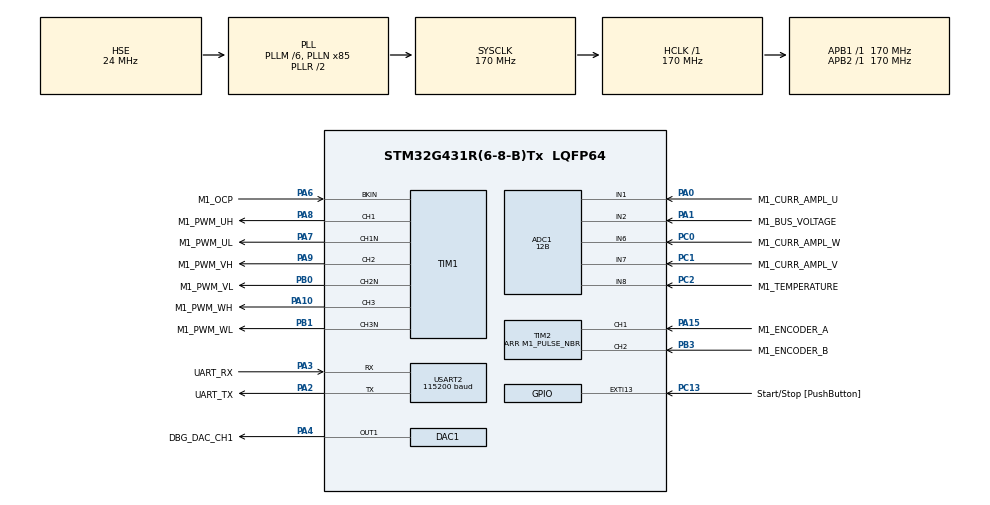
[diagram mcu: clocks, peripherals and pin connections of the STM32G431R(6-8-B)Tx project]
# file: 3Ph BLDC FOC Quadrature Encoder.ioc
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ADC1.Channel-1\#ChannelRegularConversion=ADC_CHANNEL_2
ADC1.Channel-2\#ChannelRegularConversion=ADC_CHANNEL_8
ADC1.ClockPrescaler=ADC_CLOCK_ASYNC_DIV1
ADC1.ContinuousConvMode=DISABLE
ADC1.DMAContinuousRequests=DISABLE
ADC1.DataAlign=ADC_DATAALIGN_LEFT
ADC1.DiscontinuousConvMode=DISABLE
ADC1.EOCSelection=ADC_EOC_SINGLE_CONV
ADC1.EnableAnalogWatchDog1=false
ADC1.EnableAnalogWatchDog2=false
ADC1.EnableAnalogWatchDog3=false
ADC1.EnableInjectedConversion=ENABLE
ADC1.EnableRegularConversion=ENABLE
ADC1.ExternalTrigConv=ADC_SOFTWARE_START
ADC1.ExternalTrigConvEdge=ADC_EXTERNALTRIGCONVEDGE_NONE
ADC1.ExternalTrigInjecConv=ADC_EXTERNALTRIGINJEC_T1_TRGO
ADC1.ExternalTrigInjecConvEdge=ADC_EXTERNALTRIGINJECCONV_EDGE_RISING
ADC1.InjNumberOfConversion=3
ADC1.InjectedChannel-1\#ChannelInjectedConversion=ADC_CHANNEL_1
ADC1.InjectedChannel-2\#ChannelInjectedConversion=ADC_CHANNEL_7
ADC1.InjectedChannel-3\#ChannelInjectedConversion=ADC_CHANNEL_6
ADC1.InjectedConvMode=None
ADC1.InjectedOffset-1\#ChannelInjectedConversion=0
ADC1.InjectedOffset-2\#ChannelInjectedConversion=0
ADC1.InjectedOffset-3\#ChannelInjectedConversion=0
ADC1.InjectedOffsetNumber-1\#ChannelInjectedConversion=ADC_OFFSET_NONE
ADC1.InjectedOffsetNumber-2\#ChannelInjectedConversion=ADC_OFFSET_NONE
ADC1.InjectedOffsetNumber-3\#ChannelInjectedConversion=ADC_OFFSET_NONE
ADC1.InjectedRank-1\#ChannelInjectedConversion=1
ADC1.InjectedRank-2\#ChannelInjectedConversion=2
ADC1.InjectedRank-3\#ChannelInjectedConversion=3
ADC1.InjectedSamplingTime-1\#ChannelInjectedConversion=ADC_SAMPLETIME_6CYCLES_5
ADC1.InjectedSamplingTime-2\#ChannelInjectedConversion=ADC_SAMPLETIME_6CYCLES_5
ADC1.InjectedSamplingTime-3\#ChannelInjectedConversion=ADC_SAMPLETIME_6CYCLES_5
ADC1.LowPowerAutoWait=DISABLE
ADC1.NbrOfConversion=2
ADC1.NbrOfConversionFlag=1
ADC1.Offset-1\#ChannelRegularConversion=0
ADC1.Offset-2\#ChannelRegularConversion=0
ADC1.OffsetNumber-1\#ChannelRegularConversion=ADC_OFFSET_NONE
ADC1.OffsetNumber-2\#ChannelRegularConversion=ADC_OFFSET_NONE
ADC1.Overrun=ADC_OVR_DATA_PRESERVED
ADC1.Rank-1\#ChannelRegularConversion=1
ADC1.Rank-2\#ChannelRegularConversion=2
ADC1.Resolution=ADC_RESOLUTION_12B
ADC1.SamplingTime-1\#ChannelRegularConversion=ADC_SAMPLETIME_47CYCLES_5
ADC1.SamplingTime-2\#ChannelRegularConversion=ADC_SAMPLETIME_47CYCLES_5
ADC1.ScanConvMode=ADC_SCAN_ENABLE
ADC1.master=1
DAC1.DAC_OutputBuffer=DAC_OUTPUTBUFFER_DISABLE
DAC1.DAC_Trigger_OUT1=DAC_TRIGGER_SOFTWARE
Dma.Request0=USART2_RX
Dma.Request1=USART2_TX
Dma.USART2_RX.0.Direction=DMA_PERIPH_TO_MEMORY
Dma.USART2_RX.0.EventEnable=DISABLE
Dma.USART2_RX.0.Instance=DMA1_Channel1
Dma.USART2_RX.0.MemDataAlignment=DMA_MDATAALIGN_BYTE
Dma.USART2_RX.0.MemInc=DMA_MINC_ENABLE
Dma.USART2_RX.0.Mode=DMA_NORMAL
Dma.USART2_RX.0.PeriphDataAlignment=DMA_PDATAALIGN_BYTE
Dma.USART2_RX.0.PeriphInc=DMA_PINC_DISABLE
Dma.USART2_RX.0.Polarity=HAL_DMAMUX_REQ_GEN_RISING
Dma.USART2_RX.0.Priority=DMA_PRIORITY_LOW
Dma.USART2_RX.0.RequestNumber=1
Dma.USART2_RX.0.SignalID=NONE
Dma.USART2_RX.0.SyncEnable=DISABLE
Dma.USART2_RX.0.SyncPolarity=HAL_DMAMUX_SYNC_NO_EVENT
Dma.USART2_RX.0.SyncRequestNumber=1
Dma.USART2_RX.0.SyncSignalID=NONE
Dma.USART2_TX.1.Direction=DMA_MEMORY_TO_PERIPH
Dma.USART2_TX.1.EventEnable=DISABLE
Dma.USART2_TX.1.Instance=DMA1_Channel2
Dma.USART2_TX.1.MemDataAlignment=DMA_MDATAALIGN_BYTE
Dma.USART2_TX.1.MemInc=DMA_MINC_ENABLE
Dma.USART2_TX.1.Mode=DMA_NORMAL
Dma.USART2_TX.1.PeriphDataAlignment=DMA_PDATAALIGN_BYTE
Dma.USART2_TX.1.PeriphInc=DMA_PINC_DISABLE
Dma.USART2_TX.1.Polarity=HAL_DMAMUX_REQ_GEN_RISING
Dma.USART2_TX.1.Priority=DMA_PRIORITY_LOW
Dma.USART2_TX.1.RequestNumber=1
Dma.USART2_TX.1.SignalID=NONE
Dma.USART2_TX.1.SyncEnable=DISABLE
Dma.USART2_TX.1.SyncPolarity=HAL_DMAMUX_SYNC_NO_EVENT
Dma.USART2_TX.1.SyncRequestNumber=1
Dma.USART2_TX.1.SyncSignalID=NONE
ExtraMW=MotorControl
ExtraMW.MotorControl.Config=MotorControl
ExtraMW.MotorControl.Mode=MotorControl
ExtraMW.MotorControl.Root=MCSDK_v6.3.0-Full/MotorControl
ExtraMW.MotorControl.Template=templates
FREERTOS.Tasks01=mediumFrequency,0,128,startMediumFrequencyTask,As weak,NULL,Dynamic,NULL,NULL;safety,1,128,StartSafetyTask,As external,NULL,Dynamic,NULL,NULL
Mcu.Family=STM32G4
Mcu.Name=STM32G431R(6-8-B)Tx
Mcu.Package=LQFP64
MotorControl.ADC_AHBPERIPH=RCC_AHBPeriph_ADC1
MotorControl.ADC_CLOCK_WB_DIV=1
MotorControl.ADC_PERIPH=ADC1
MotorControl.ADC_REFERENCE_VOLTAGE=3.3
MotorControl.BOARD=NUCLEO-G431RB
MotorControl.BUS_VOLTAGE_READING=true
MotorControl.CCMRAM_ENABLED=false
MotorControl.CLOCK_FREQUENCY=CPU_CLK_170_MHZ
MotorControl.CLOCK_SOURCE=EXTERNAL
MotorControl.CPU_CLK_170_MHZ=true
MotorControl.CTLBOARD_NAME=NUCLEO-G431RB
MotorControl.CUBE_MX_VER=6.12.0
MotorControl.CURRENT_READING_TOPOLOGY=THREE_SHUNT
MotorControl.CURR_SAMPLING_TIME=6
MotorControl.DAC_NAME=DAC1
MotorControl.DBG_MCU_LOAD_MEASURE=false
MotorControl.DEBUG_DAC_CH1=true
MotorControl.DEBUG_DAC_CH1_EN=true
MotorControl.DEBUG_DAC_FUNCTIONALITY_EN=true
MotorControl.DRIVES_NUMBER_SELECTION=SINGLEDRIVE
MotorControl.DRIVE_NUMBER=1
MotorControl.DRIVE_TYPE=FOC
MotorControl.EMERGENCY_STOP_GPIO_PIN=LL_GPIO_PIN_6
MotorControl.EMERGENCY_STOP_GPIO_PORT=GPIOA
MotorControl.ENCODER=true
MotorControl.ENCODER_AVAILABLE=true
MotorControl.ENCODER_PPR=2048
MotorControl.ENC_A_GPIO_PIN=LL_GPIO_PIN_15
MotorControl.ENC_A_GPIO_PORT=GPIOA
MotorControl.ENC_B_GPIO_PIN=LL_GPIO_PIN_3
MotorControl.ENC_B_GPIO_PORT=GPIOB
MotorControl.ENC_ICx_FILTER=119
MotorControl.ENC_INVERT_SPEED=false
MotorControl.ENC_TIMER_SELECTION=ENC_TIM2
MotorControl.ENC_USE_CH3=false
MotorControl.EXT_CLK_24_MHZ=true
MotorControl.EXT_CLOCK_FREQUENCY=EXT_CLK_24_MHZ
MotorControl.FEEDBACK_NET_FILTERING=false
MotorControl.HALL_SENSORS_AVAILABLE=false
MotorControl.HIGH_SIDE_IDLE_STATE=false
MotorControl.HWV_CS=ThreeShunt_AmplifiedCurrents
MotorControl.HWV_OCP=OnPowerStageOCP
MotorControl.HWV_PWM=DrivingHighAndLowSides
MotorControl.HW_COMPLEMENTED_LOW_SIDE=false
MotorControl.HW_DEAD_TIME_NS=1000
MotorControl.IPs=CORDIC,SYS,NVIC,RCC,MotorControl,TIM1,ADC1,TIM2,DAC1,USART2,FREERTOS,DMA
MotorControl.LOW_MEMORY_FOOTPRINT_REG=false
MotorControl.LOW_SIDE_IDLE_STATE=false
MotorControl.LOW_SIDE_SIGNALS_ENABLING=LS_PWM_TIMER
MotorControl.M1_ALIGNMENT_ANGLE_DEG=90
MotorControl.M1_ALIGNMENT_DURATION=700
MotorControl.M1_AMPLIFICATION_GAIN=5.18
MotorControl.M1_ANGC={0,0,0,0,0,0,0,0}
MotorControl.M1_AUXILIARY_SPEED_SENSOR=NONE
MotorControl.M1_BOARD_MAX_CURRENT=4.97
MotorControl.M1_BUS_VOLTAGE_READING=true
MotorControl.M1_COMMUTATION_STEP_TIME_BUF_SIZE=12
MotorControl.M1_CONSTANT1_D=1857278
MotorControl.M1_CONSTANT1_Q=1857278
MotorControl.M1_CONSTANT2_QD=16970
MotorControl.M1_CS_ADC_NUM=1
MotorControl.M1_CS_ADC_PHASE_SHARED=NONE
MotorControl.M1_CS_ADC_U=ADC1
MotorControl.M1_CS_ADC_V=ADC1
MotorControl.M1_CS_ADC_W=ADC1
MotorControl.M1_CS_CHANNEL_U=1
MotorControl.M1_CS_CHANNEL_V=7
MotorControl.M1_CS_CHANNEL_W=6
MotorControl.M1_CURRENT_AMPLIFICATION_TOPO=EXTERNAL
MotorControl.M1_CURRENT_SENSING_TOPO=THREE_SHUNT
MotorControl.M1_CURR_SAMPLING_TIME=6
MotorControl.M1_DBG_OPEN_LOOP_ENABLE=false
MotorControl.M1_DC_CURRENT_RS_MEAS=4.97
MotorControl.M1_DEFAULT_CONTROL_MODE=STC_SPEED_MODE
MotorControl.M1_DEFAULT_FLUX_COMPONENT=0
MotorControl.M1_DEFAULT_TARGET_SPEED_RPM=3600
MotorControl.M1_DEFAULT_TORQUE_COMPONENT=0
MotorControl.M1_DISCONTINUOUS_PWM=false
MotorControl.M1_DP_TOPOLOGY=NONE
MotorControl.M1_DRIVE_TYPE=FOC
MotorControl.M1_ENCODER_PPR=2048
MotorControl.M1_ENC_AVERAGING_FIFO_DEPTH=8
MotorControl.M1_ENC_A_GPIO_PIN=LL_GPIO_PIN_15
MotorControl.M1_ENC_A_GPIO_PORT=GPIOA
MotorControl.M1_ENC_B_GPIO_PIN=LL_GPIO_PIN_3
MotorControl.M1_ENC_B_GPIO_PORT=GPIOB
MotorControl.M1_ENC_ICx_FILTER=119
MotorControl.M1_ENC_TIMER_SELECTION=ENC_TIM2
MotorControl.M1_ENC_USE_CH3=false
MotorControl.M1_FEED_FORWARD_CURRENT_REG_ENABLING=false
MotorControl.M1_FINAL_I_ALIGNMENT=4.97
MotorControl.M1_FLUX_WEAKENING_ENABLING=false
MotorControl.M1_FW_KIDIV=32768
MotorControl.M1_FW_KI_GAIN=5000
MotorControl.M1_FW_KPDIV=32768
MotorControl.M1_FW_KP_GAIN=3000
MotorControl.M1_FW_VOLTAGE_REF=985
MotorControl.M1_HALL_PHASE_SHIFT=300
MotorControl.M1_HALL_SENSORS_PLACEMENT=DEGREES_120
MotorControl.M1_HIGH_SIDE_IDLE_STATE=false
MotorControl.M1_HW_DEAD_TIME_NS=1000
MotorControl.M1_ICL_ENABLED=false
MotorControl.M1_ID_DEMAG=-4.97
MotorControl.M1_IQMAX=4.97
MotorControl.M1_LDLQ_RATIO=1.000
MotorControl.M1_LOW_SIDE_IDLE_STATE=false
MotorControl.M1_LOW_SIDE_SIGNALS_ENABLING=LS_PWM_TIMER
MotorControl.M1_LS=0.00224
MotorControl.M1_MAX_APPLICATION_SPEED=10000
MotorControl.M1_MAX_MODULATION_INDEX=100
MotorControl.M1_MIN_APPLICATION_SPEED=0
MotorControl.M1_MOTOR_MAX_SPEED_RPM=10000
MotorControl.M1_MOTOR_NAME=Maxon EC45 Flat 42.9mm
MotorControl.M1_MOTOR_RATED_FLUX=0.032761925
MotorControl.M1_MOTOR_VOLTAGE_CONSTANT=5.4
MotorControl.M1_MTPA_ENABLING=false
MotorControl.M1_NOMINAL_BUS_VOLTAGE_V=24
MotorControl.M1_NOMINAL_CURRENT=4.97
MotorControl.M1_OCP_BKIN_FILTER=3
MotorControl.M1_OCP_BKIN_MODE=EXT_MODE
MotorControl.M1_OCP_BKIN_POLARITY=EMSTOP_ACTIVE_LOW
MotorControl.M1_OCP_DESTINATION=TIM_BKIN
MotorControl.M1_OCP_TOPOLOGY=EXTERNAL
MotorControl.M1_OFST={0,0,0,0,0,0,0,0}
MotorControl.M1_ON_OVER_VOLTAGE=TURN_OFF_PWM
MotorControl.M1_OVERMODULATION=false
MotorControl.M1_OVP_THRESHOLD_HIGH=29
MotorControl.M1_OV_TEMPERATURE_HYSTERESIS_C=10
MotorControl.M1_OV_TEMPERATURE_PROT_ENABLING=true
MotorControl.M1_OV_TEMPERATURE_THRESHOLD_C=110
MotorControl.M1_OV_VOLTAGE_PROT_ENABLING=true
MotorControl.M1_OV_VOLTAGE_THRESHOLD_V=29
MotorControl.M1_PID_FLUX_KD_DEFAULT=100
MotorControl.M1_PID_FLUX_KI_DEFAULT=2461
MotorControl.M1_PID_FLUX_KP_DEFAULT=2283
MotorControl.M1_PID_SPEED_KD_DEFAULT=0
MotorControl.M1_PID_SPEED_KI_DEFAULT=430
MotorControl.M1_PID_SPEED_KP_DEFAULT=2222
MotorControl.M1_PID_TORQUE_KD_DEFAULT=100
MotorControl.M1_PID_TORQUE_KI_DEFAULT=2461
MotorControl.M1_PID_TORQUE_KP_DEFAULT=2283
MotorControl.M1_POLE_PAIR_NUM=8
MotorControl.M1_POSITION_CTRL_ENABLING=true
MotorControl.M1_POSITION_CTRL_KDDIV=16
MotorControl.M1_POSITION_CTRL_KD_GAIN=1000
MotorControl.M1_POSITION_CTRL_KIDIV=32768
MotorControl.M1_POSITION_CTRL_KI_GAIN=1000
MotorControl.M1_POSITION_CTRL_KPDIV=1024
MotorControl.M1_POSITION_CTRL_KP_GAIN=10000
MotorControl.M1_POSITION_LOOP_FREQUENCY_HZ=1000
MotorControl.M1_POTENTIOMETER_ENABLE=false
MotorControl.M1_POWERBOARD_NAME=X-NUCLEO-IHM08M1
MotorControl.M1_PWM_CHARGE_BOOT_CAP_DUTY_CYCLES=0.000
MotorControl.M1_PWM_CHARGE_BOOT_CAP_MS=10
MotorControl.M1_PWM_DRIVER_PN=L6398
MotorControl.M1_PWM_FREQUENCY=16000
MotorControl.M1_PWM_TIMER_BRK_IRQ=TIM1_BRK_TIM15
MotorControl.M1_PWM_TIMER_SELECTION=PWM_TIM1
MotorControl.M1_PWM_TIMER_UP_IRQ=TIM1_UP_TIM16
MotorControl.M1_REGULATION_EXECUTION_RATE=1
MotorControl.M1_RS=4.83
MotorControl.M1_RSHUNT=0.01
MotorControl.M1_SEGDIV=0
MotorControl.M1_SHARED_SIGNAL_ENABLE=false
MotorControl.M1_SPD_DIFFERENTIAL_TERM_ENABLING=false
MotorControl.M1_SPEED_SENSOR=QUAD_ENCODER
MotorControl.M1_SP_KDDIV=16
MotorControl.M1_SP_KIDIV=16384
MotorControl.M1_SP_KPDIV=128
MotorControl.M1_SS_MEAS_ERRORS_BEFORE_FAULTS=3
MotorControl.M1_SW_DEADTIME_NS=850
MotorControl.M1_T0_C=25
MotorControl.M1_TEMPERATURE_READING=true
MotorControl.M1_TEMP_ADC_SAMPLING_TIME=47
MotorControl.M1_TEMP_FDBK_ADC=ADC1
MotorControl.M1_TEMP_FDBK_CHANNEL=ADC_CHANNEL_8
MotorControl.M1_TF_KDDIV=8192
MotorControl.M1_TF_KIDIV=512
MotorControl.M1_TF_KPDIV=64
MotorControl.M1_TNOISE_NS=1000
MotorControl.M1_TRISE_NS=1000
MotorControl.M1_T_MAX=110
MotorControl.M1_UD_VOLTAGE_THRESHOLD_V=10
MotorControl.M1_USE_INTERNAL_OPAMP=false
MotorControl.M1_UV_VOLTAGE_PROT_ENABLING=true
MotorControl.M1_V0_V=1.055
MotorControl.M1_VBUS_ADC=ADC1
MotorControl.M1_VBUS_ADC_SAMPLING_TIME=47
MotorControl.M1_VBUS_CHANNEL=ADC_CHANNEL_2
MotorControl.M1_VBUS_PARTITIONING_FACTOR=0.052164840897235255
MotorControl.M1_dV_dT=0.023
MotorControl.MAX_READABLE_CURRENT=31.845
MotorControl.MCPA_OVER_UART_A_STREAM=10
MotorControl.MCP_ASPEP_OVER_UART=true
MotorControl.MCP_ASYNC_EN=true
MotorControl.MCP_ASYNC_OVER_ASPEP_EN=true
MotorControl.MCP_ASYNC_OVER_UART_A_EN=true
MotorControl.MCP_DMACH_RX_UART_A=1
MotorControl.MCP_DMACH_TX_UART_A=2
MotorControl.MCP_DMA_RX_UART_A=DMA1
MotorControl.MCP_DMA_TX_UART_A=DMA1
MotorControl.MCP_EN=true
MotorControl.MCP_IRQ_HANDLER_DMA_RX_UART_A=DMA1_Channel1_IRQHandler
MotorControl.MCP_IRQ_HANDLER_UART_A=USART2_IRQHandler
MotorControl.MCP_OVER_ASPEP_EN=true
MotorControl.MCP_OVER_STLNK_EN=false
MotorControl.MCP_OVER_UART_A_EN=true
MotorControl.MCP_OVER_UART_B_EN=false
MotorControl.MCP_RX_SYNC_PAYLOAD_MAX=128
MotorControl.MCP_TX_ASYNC_PAYLOAD_MAX_UART_A=2048
MotorControl.MCP_TX_SYNC_PAYLOAD_MAX=128
MotorControl.MCU=STM32G431RB
MotorControl.MCU_FAMILY=STM32G4
MotorControl.MCU_LINE=STM32G4x1
MotorControl.MCU_NAME=STM32G431R(6-8-B)Tx
MotorControl.MCU_PACKAGE=LQFP64
MotorControl.MCU_TYPE=STM32G431RB
MotorControl.MCU_USERNAME=STM32G431RBTx
MotorControl.MC_WORKBENCH_VERSION=6.3.0
MotorControl.MOTOR_PROFILER=false
MotorControl.MOTOR_TYPE=PMSM
MotorControl.ON_OVER_VOLTAGE=TURN_OFF_PWM
MotorControl.OV_TEMPERATURE_PROT_ENABLING=true
MotorControl.OV_VOLTAGE_PROT_ENABLING=true
MotorControl.PHASE_UH_GPIO_PIN=LL_GPIO_PIN_8
MotorControl.PHASE_UH_GPIO_PORT=GPIOA
MotorControl.PHASE_UH_POLARITY=H_ACTIVE_HIGH
MotorControl.PHASE_UL_GPIO_PIN=LL_GPIO_PIN_7
MotorControl.PHASE_UL_GPIO_PORT=GPIOA
MotorControl.PHASE_UL_POLARITY=L_ACTIVE_LOW
MotorControl.PHASE_U_CURR_ADC=ADC1
MotorControl.PHASE_U_CURR_CHANNEL=ADC_CHANNEL_1
MotorControl.PHASE_U_GPIO_PIN=LL_GPIO_PIN_0
MotorControl.PHASE_U_GPIO_PORT=GPIOA
MotorControl.PHASE_VH_GPIO_PIN=LL_GPIO_PIN_9
MotorControl.PHASE_VH_GPIO_PORT=GPIOA
MotorControl.PHASE_VH_POLARITY=H_ACTIVE_HIGH
MotorControl.PHASE_VL_GPIO_PIN=LL_GPIO_PIN_0
MotorControl.PHASE_VL_GPIO_PORT=GPIOB
MotorControl.PHASE_VL_POLARITY=L_ACTIVE_LOW
MotorControl.PHASE_V_CURR_ADC=ADC1
MotorControl.PHASE_V_CURR_CHANNEL=ADC_CHANNEL_7
MotorControl.PHASE_V_GPIO_PIN=LL_GPIO_PIN_1
MotorControl.PHASE_V_GPIO_PORT=GPIOC
MotorControl.PHASE_WH_GPIO_PIN=LL_GPIO_PIN_10
MotorControl.PHASE_WH_GPIO_PORT=GPIOA
MotorControl.PHASE_WH_POLARITY=H_ACTIVE_HIGH
MotorControl.PHASE_WL_GPIO_PIN=LL_GPIO_PIN_1
MotorControl.PHASE_WL_GPIO_PORT=GPIOB
MotorControl.PHASE_WL_POLARITY=L_ACTIVE_LOW
MotorControl.PHASE_W_CURR_ADC=ADC1
MotorControl.PHASE_W_CURR_CHANNEL=ADC_CHANNEL_6
MotorControl.PHASE_W_GPIO_PIN=LL_GPIO_PIN_0
MotorControl.PHASE_W_GPIO_PORT=GPIOC
MotorControl.POTENTIOMETER_READING=false
MotorControl.PWM_FREQUENCY=16000
MotorControl.PWM_TIMER_SELECTION=PWM_TIM1
MotorControl.REGULATION_EXECUTION_RATE=1
MotorControl.RTOS=FREERTOS
MotorControl.RTOS_IRQ_NAME_WB2MX=TIM6_DAC_IRQn
MotorControl.RTOS_TIMER=TIM6
MotorControl.RTOS_USE_IRQ=true
MotorControl.R_BRAKE_SWITCH_OFF_THRES_V=23
MotorControl.SINGLEDRIVE=true
MotorControl.SPD_DIFFERENTIAL_TERM_ENABLING=false
MotorControl.SPEED_SENSOR_SELECTION=ENCODER
MotorControl.START_STOP_BTN=true
MotorControl.START_STOP_GPIO_PIN=LL_GPIO_PIN_13
MotorControl.START_STOP_GPIO_PORT=GPIOC
MotorControl.START_STOP_POLARITY=DIN_ACTIVE_LOW
MotorControl.START_STOP_POLARITY_EDGE=GPIO_NOPULL
MotorControl.STM32G431RB=true
MotorControl.SW_DEADTIME_NS=850
MotorControl.TEMPERATURE_READING=true
MotorControl.TEMP_ADC_SAMPLING_TIME=47
MotorControl.TEMP_FDBK_ADC=ADC1
MotorControl.TEMP_FDBK_CHANNEL=ADC_CHANNEL_8
MotorControl.TEMP_FDBK_GPIO_PIN=LL_GPIO_PIN_2
MotorControl.TEMP_FDBK_GPIO_PORT=GPIOC
MotorControl.TFDIFFERENTIAL_TERM_ENABLING=false
MotorControl.THREE_SHUNT=true
MotorControl.TRISE_NS=1000
MotorControl.USART_RX_GPIO_PIN=LL_GPIO_PIN_3
MotorControl.USART_RX_GPIO_PORT=GPIOA
MotorControl.USART_SELECTION=USE_USART2
MotorControl.USART_SELECTION_A=USART2
MotorControl.USART_SPEED=115200
MotorControl.USART_TX_GPIO_PIN=LL_GPIO_PIN_2
MotorControl.USART_TX_GPIO_PORT=GPIOA
MotorControl.USE_3OPAMPS=false
MotorControl.USE_INTERNAL_OPAMP=false
MotorControl.UV_VOLTAGE_PROT_ENABLING=true
MotorControl.VBUS_ADC=ADC1
MotorControl.VBUS_ADC_SAMPLING_TIME=47
MotorControl.VBUS_CHANNEL=ADC_CHANNEL_2
MotorControl.VBUS_GPIO_PIN=LL_GPIO_PIN_1
MotorControl.VBUS_GPIO_PORT=GPIOA
MotorControl.WB_UI_CUTOFF_FREQUENCY=6000
MotorControl.WB_UI_DAC_CH1_PIN=PA4
MotorControl.WB_UI_ENCODER_HAS_INDEX_PIN=false
MotorControl.WB_UI_FLUX_TARGET=0
MotorControl.WB_UI_FRICTION=14
MotorControl.WB_UI_INERTIA=9.25
MotorControl.WB_UI_MAGNETIC_STRUCTURE=SM-PMSM
MotorControl.WB_UI_MAX_CURRENT=4.97
MotorControl.WB_UI_MAX_NOMINAL_DC_VOLTAGE=24
MotorControl.WB_UI_MAX_PWMFREQUENCY=100000
MotorControl.WB_UI_MOTOR_DESCRIPTION=brushless DC motor with encoder and Z Index
MotorControl.WB_UI_OCP_DISABLING_ENABLE=false
MotorControl.WB_UI_OCP_THRESHOLD=30
MotorControl.WB_UI_PW_BOARD_MAX_RATED_CURRENT=30
MotorControl.WB_UI_PW_BOARD_MAX_VOLTAGE=48
MotorControl.WB_UI_PW_BOARD_MIN_VOLTAGE=10
MotorControl.WB_UI_VPOL=1.71
MotorControl.WB_to_Mx_template_version=24-04-17
MotorControl.WB_to_Mx_version=6.2.3
NVIC.ADC1_2_IRQn=true\:7\:0\:true\:true\:false\:5\:true\:true\:true\:true
NVIC.DMA1_Channel1_IRQn=true\:8\:0\:true\:true\:false\:2\:true\:true\:true\:true
NVIC.EXTI15_10_IRQn=true\:8\:0\:true\:true\:false\:7\:true\:true\:true\:true
NVIC.PriorityGroup=NVIC_PRIORITYGROUP_4
NVIC.TIM1_BRK_TIM15_IRQn=true\:9\:0\:true\:true\:false\:3\:true\:true\:true\:true
NVIC.TIM1_UP_TIM16_IRQn=true\:5\:0\:true\:true\:false\:4\:true\:true\:true\:true
NVIC.TIM2_IRQn=true\:8\:0\:true\:true\:false\:6\:true\:true\:true\:true
NVIC.TIM6_DAC_IRQn=true\:0\:0\:false\:false\:true\:false\:false\:true\:true
NVIC.TimeBase=TIM6_DAC_IRQn
NVIC.TimeBaseIP=TIM6
NVIC.USART2_IRQn=true\:8\:0\:true\:true\:false\:1\:true\:true\:true\:true
PA0.GPIO_Label=M1_CURR_AMPL_U
PA0.Mode=IN1-Single-Ended
PA0.Signal=ADC1_IN1
PA1.GPIO_Label=M1_BUS_VOLTAGE
PA1.Mode=IN2-Single-Ended
PA1.Signal=ADC1_IN2
PA10.GPIO_Label=M1_PWM_WH
PA10.GPIO_PuPd=GPIO_PULLDOWN
PA10.GPIO_Speed=GPIO_SPEED_FREQ_HIGH
PA10.Signal=S_TIM1_CH3
PA13.GPIO_Label=TMS
PA13.Mode=Serial_Wire
PA13.Signal=SYS_JTMS-SWDIO
PA14.GPIO_Label=TCK
PA14.Mode=Serial_Wire
PA14.Signal=SYS_JTCK-SWCLK
PA15.GPIO_Label=M1_ENCODER_A
PA15.Signal=S_TIM2_CH1
PA2.GPIO_Label=UART_TX
PA2.GPIO_Mode=GPIO_MODE_AF_PP
PA2.GPIO_PuPd=GPIO_NOPULL
PA2.GPIO_Speed=GPIO_SPEED_FREQ_LOW
PA2.Mode=Asynchronous
PA2.Signal=USART2_TX
PA3.GPIO_Label=UART_RX
PA3.GPIO_Mode=GPIO_MODE_AF_PP
PA3.GPIO_PuPd=GPIO_NOPULL
PA3.GPIO_Speed=GPIO_SPEED_FREQ_LOW
PA3.Mode=Asynchronous
PA3.Signal=USART2_RX
PA4.GPIO_Label=DBG_DAC_CH1
PA4.Signal=COMP_DAC11_group
PA6.GPIO_Label=M1_OCP
PA6.GPIO_PuPd=GPIO_PULLUP
PA6.Mode=Activate-Break-Input
PA6.Signal=TIM1_BKIN
PA7.GPIO_Label=M1_PWM_UL
PA7.GPIO_PuPd=GPIO_PULLUP
PA7.GPIO_Speed=GPIO_SPEED_FREQ_HIGH
PA7.Mode=PWM Generation1 CH1 CH1N
PA7.Signal=TIM1_CH1N
PA8.GPIO_Label=M1_PWM_UH
PA8.GPIO_PuPd=GPIO_PULLDOWN
PA8.GPIO_Speed=GPIO_SPEED_FREQ_HIGH
PA8.Signal=S_TIM1_CH1
PA9.GPIO_Label=M1_PWM_VH
PA9.GPIO_PuPd=GPIO_PULLDOWN
PA9.GPIO_Speed=GPIO_SPEED_FREQ_HIGH
PA9.Signal=S_TIM1_CH2
PB0.GPIO_Label=M1_PWM_VL
PB0.GPIO_PuPd=GPIO_PULLUP
PB0.GPIO_Speed=GPIO_SPEED_FREQ_HIGH
PB0.Mode=PWM Generation2 CH2 CH2N
PB0.Signal=TIM1_CH2N
PB1.GPIO_Label=M1_PWM_WL
PB1.GPIO_PuPd=GPIO_PULLUP
PB1.GPIO_Speed=GPIO_SPEED_FREQ_HIGH
PB1.Mode=PWM Generation3 CH3 CH3N
PB1.Signal=TIM1_CH3N
PB3.GPIO_Label=M1_ENCODER_B
PB3.Signal=S_TIM2_CH2
PC0.GPIO_Label=M1_CURR_AMPL_W
PC0.Mode=IN6-Single-Ended
PC0.Signal=ADC1_IN6
PC1.GPIO_Label=M1_CURR_AMPL_V
PC1.Mode=IN7-Single-Ended
PC1.Signal=ADC1_IN7
PC13.GPIO_Label=Start/Stop [PushButton]
PC13.GPIO_ModeDefaultEXTI=GPIO_MODE_IT_FALLING
PC13.GPIO_PuPd=GPIO_NOPULL
PC13.Signal=GPXTI13
PC2.GPIO_Label=M1_TEMPERATURE
PC2.Mode=IN8-Single-Ended
PC2.Signal=ADC1_IN8
PF0-OSC_IN.Mode=HSE-External-Oscillator
PF0-OSC_IN.Signal=RCC_OSC_IN
PF1-OSC_OUT.Mode=HSE-External-Oscillator
PF1-OSC_OUT.Signal=RCC_OSC_OUT
ProjectManager.HeapSize=0x200
ProjectManager.StackSize=0x400
ProjectManager.TargetToolchain=STM32CubeIDE
RCC.ADC12CLockSelection=RCC_ADC12CLKSOURCE_PLL
RCC.ADC12Freq_Value=42500000
RCC.AHBFreq_Value=170000000
RCC.APB1Freq_Value=170000000
RCC.APB1TimFreq_Value=170000000
RCC.APB2Freq_Value=170000000
RCC.APB2TimFreq_Value=170000000
RCC.CK48CLockSelection=RCC_USBCLKSOURCE_PLL
RCC.CortexFreq_Value=170000000
RCC.EXTERNAL_CLOCK_VALUE=12288000
RCC.EnbaleCSS=true
RCC.HCLKFreq_Value=170000000
RCC.HSE_VALUE=24000000
RCC.HSI48_VALUE=48000000
RCC.HSI_VALUE=16000000
RCC.LSE_VALUE=32768
RCC.PLLM=RCC_PLLM_DIV6
RCC.PLLN=85
RCC.PLLP=RCC_PLLP_DIV8
RCC.PLLSourceVirtual=RCC_PLLSOURCE_HSE
RCC.PREFETCH_ENABLE=1
RCC.SYSCLKFreq_VALUE=170000000
RCC.SYSCLKSource=RCC_SYSCLKSOURCE_PLLCLK
RCC.USBFreq_Value=170000000
RCC.VCOOutputFreq_Value=340000000
SH.COMP_DAC11_group.0=DAC1_OUT1,DAC_OUT1
SH.S_TIM1_CH1.0=TIM1_CH1,PWM Generation1 CH1 CH1N
SH.S_TIM1_CH2.0=TIM1_CH2,PWM Generation2 CH2 CH2N
SH.S_TIM1_CH3.0=TIM1_CH3,PWM Generation3 CH3 CH3N
SH.S_TIM2_CH1.0=TIM2_CH1,Encoder_Interface
SH.S_TIM2_CH2.0=TIM2_CH2,Encoder_Interface
TIM1.AutoReloadPreload=TIM_AUTORELOAD_PRELOAD_DISABLE
TIM1.AutomaticOutput=TIM_AUTOMATICOUTPUT_DISABLE
TIM1.Break2Filter=3
TIM1.Break2Polarity=TIM_BREAK2POLARITY_HIGH
TIM1.Break2State=TIM_BREAK2_DISABLE
TIM1.BreakFilter=3
TIM1.BreakPolarity=TIM_BREAKPOLARITY_HIGH
TIM1.BreakState=TIM_BREAK_ENABLE
TIM1.Channel=TIM_CHANNEL_4
TIM1.Channel-PWM\ Generation1\ CH1\ CH1N=TIM_CHANNEL_1
TIM1.Channel-PWM\ Generation2\ CH2\ CH2N=TIM_CHANNEL_2
TIM1.Channel-PWM\ Generation3\ CH3\ CH3N=TIM_CHANNEL_3
TIM1.Channel-PWM\ Generation4\ No\ Output=TIM_CHANNEL_4
TIM1.ClearInputSource=TIM_CLEARINPUTSOURCE_NONE
TIM1.ClockDivision=TIM_CLOCKDIVISION_DIV2
TIM1.CounterMode=TIM_COUNTERMODE_CENTERALIGNED1
TIM1.DeadTime=((DEAD_TIME_COUNTS) / 2)
TIM1.LockLevel=TIM_LOCKLEVEL_OFF
TIM1.OC1Preload_PWM=ENABLE
TIM1.OC2Preload_PWM=ENABLE
TIM1.OC3Preload_PWM=ENABLE
TIM1.OC4Preload_PWM=ENABLE
TIM1.OCFastMode_PWM=TIM_OCFAST_DISABLE
TIM1.OCIdleState_1=TIM_OCIDLESTATE_RESET
TIM1.OCIdleState_2=TIM_OCIDLESTATE_RESET
TIM1.OCIdleState_3=TIM_OCIDLESTATE_RESET
TIM1.OCIdleState_4=TIM_OCIDLESTATE_RESET
TIM1.OCMode_PWM-PWM\ Generation1\ CH1\ CH1N=TIM_OCMODE_PWM1
TIM1.OCMode_PWM-PWM\ Generation2\ CH2\ CH2N=TIM_OCMODE_PWM1
TIM1.OCMode_PWM-PWM\ Generation3\ CH3\ CH3N=TIM_OCMODE_PWM1
TIM1.OCMode_PWM-PWM\ Generation4\ No\ Output=TIM_OCMODE_PWM2
TIM1.OCNIdleState_1=TIM_OCNIDLESTATE_SET
TIM1.OCNIdleState_2=TIM_OCNIDLESTATE_SET
TIM1.OCNIdleState_3=TIM_OCNIDLESTATE_SET
TIM1.OCNPolarity_1=TIM_OCNPOLARITY_LOW
TIM1.OCNPolarity_2=TIM_OCNPOLARITY_LOW
TIM1.OCNPolarity_3=TIM_OCNPOLARITY_LOW
TIM1.OCPolarity_1=TIM_OCPOLARITY_HIGH
TIM1.OCPolarity_2=TIM_OCPOLARITY_HIGH
TIM1.OCPolarity_3=TIM_OCPOLARITY_HIGH
TIM1.OCPolarity_4=TIM_OCPOLARITY_HIGH
TIM1.OffStateIDLEMode=TIM_OSSI_ENABLE
TIM1.OffStateRunMode=TIM_OSSR_ENABLE
TIM1.PeriodNoDither=((PWM_PERIOD_CYCLES) / 2)
TIM1.Prescaler=((TIM_CLOCK_DIVIDER) - 1)
TIM1.PulseNoDither_1=((PWM_PERIOD_CYCLES) / 4)
TIM1.PulseNoDither_2=((PWM_PERIOD_CYCLES) / 4)
TIM1.PulseNoDither_3=((PWM_PERIOD_CYCLES) / 4)
TIM1.PulseNoDither_4=(((PWM_PERIOD_CYCLES) / 2) - (HTMIN))
TIM1.RepetitionCounter=(REP_COUNTER)
TIM1.SourceBRK2DigInput=TIM_BREAKINPUTSOURCE_DISABLE
TIM1.SourceBRKDigInput=TIM_BREAKINPUTSOURCE_ENABLE
TIM1.SourceBRKDigInputPolarity=TIM_BREAKINPUTSOURCE_POLARITY_LOW
TIM1.TIM_MasterOutputTrigger=TIM_TRGO_OC4REF
TIM1.TIM_MasterOutputTrigger2=TIM_TRGO2_RESET
TIM1.TIM_MasterSlaveMode=TIM_MASTERSLAVEMODE_DISABLE
TIM1.TIM_SlaveMode=TIM_SLAVEMODE_TRIGGER
TIM2.EncoderMode=TIM_ENCODERMODE_TI12
TIM2.IC1Filter=M1_ENC_IC_FILTER
TIM2.IC1Polarity=TIM_ICPOLARITY_RISING
TIM2.IC2Filter=M1_ENC_IC_FILTER
TIM2.IC2Polarity=TIM_ICPOLARITY_RISING
TIM2.PeriodNoDither=M1_PULSE_NBR
USART2.BaudRate=115200
USART2.VirtualMode-Asynchronous=VM_ASYNC
USART2.WordLength=WORDLENGTH_8B
VP_CORDIC_VS_CORDIC.Mode=CORDIC_Activate
VP_FREERTOS_VS_CMSIS_V1.Mode=CMSIS_V1
VP_MotorControl_MC_ENABLED.Mode=Enabled
VP_SYS_VS_DBSignals.Mode=DisableDeadBatterySignals
VP_SYS_VS_tim6.Mode=TIM6
VP_TIM1_VS_no_output4.Mode=PWM Generation4 No Output
board=custom

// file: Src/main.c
/* USER CODE BEGIN Header */
/**
  ******************************************************************************
  * @file           : main.c
  * @brief          : Main program body
  ******************************************************************************
  * @attention
  *
  * Copyright (c) 2024 STMicroelectronics.
  * All rights reserved.
  *
  * This software is licensed under terms that can be found in the LICENSE file
  * in the root directory of this software component.
  * If no LICENSE file comes with this software, it is provided AS-IS.
  *
  ******************************************************************************
  */
/* USER CODE END Header */
#include "main.h"
#include "cmsis_os.h"
#include "mc_api.c"

/* USER CODE BEGIN Includes */
#define PI 3.14159265358979323846
/* USER CODE END Includes */

ADC_HandleTypeDef hadc1;

CORDIC_HandleTypeDef hcordic;

DAC_HandleTypeDef hdac1;

TIM_HandleTypeDef htim1;
TIM_HandleTypeDef htim2;

UART_HandleTypeDef huart2;
DMA_HandleTypeDef hdma_usart2_rx;
DMA_HandleTypeDef hdma_usart2_tx;

osThreadId mediumFrequencyHandle;
osThreadId safetyHandle;
/* USER CODE BEGIN PV */
/*float targetPosition = 0.0f;  // Target position in radians*/
/*volatile bool startMotor = false;      // Global flag to control the motor state*/
/* USER CODE END PV */

void SystemClock_Config(void);
static void MX_GPIO_Init(void);
static void MX_DMA_Init(void);
static void MX_ADC1_Init(void);
static void MX_CORDIC_Init(void);
static void MX_DAC1_Init(void);
static void MX_TIM1_Init(void);
static void MX_TIM2_Init(void);
static void MX_USART2_UART_Init(void);
void startMediumFrequencyTask(void const * argument);
extern void StartSafetyTask(void const * argument);

static void MX_NVIC_Init(void);

static float degreesToRadians(float degrees) {
    return (degrees * PI / 180.0f);
}

/* Global variables */
float targetPosition = 0.0f;  // Global variable for motor target position
bool startMotor = false;      // Global flag to start the motor

int main(void)
{

  /* MCU Configuration--------------------------------------------------------*/

  /* Reset of all peripherals, Initializes the Flash interface and the Systick. */
  HAL_Init();

  /* Configure the system clock */
  SystemClock_Config();

  /* Initialize all configured peripherals */
  MX_GPIO_Init();
  MX_DMA_Init();
  MX_ADC1_Init();
  MX_CORDIC_Init();
  MX_DAC1_Init();
  MX_TIM1_Init();
  MX_TIM2_Init();
  MX_USART2_UART_Init();
  MX_MotorControl_Init();

  /* Initialize interrupts */
  MX_NVIC_Init();
  /* USER CODE BEGIN 2 */

  /* Set initial target position and start motor flag */
  targetPosition = degreesToRadians(90.0f);  // Set target position to 90 degrees
  startMotor = true;

  /* USER CODE END 2 */

  /* Create the thread(s) */
  /* definition and creation of mediumFrequency */
  osThreadDef(mediumFrequency, startMediumFrequencyTask, osPriorityNormal, 0, 128);
  mediumFrequencyHandle = osThreadCreate(osThread(mediumFrequency), NULL);

  /* definition and creation of safety */
  osThreadDef(safety, StartSafetyTask, osPriorityAboveNormal, 0, 128);
  safetyHandle = osThreadCreate(osThread(safety), NULL);

  MC_StartMotor1();
  MC_ProgramPositionCommandMotor1(targetPosition, 0); // Immediate movement
  MC_StopMotor1();

//	if (startMotor) {
//	  MC_StartMotor1();
//	  if (MC_StartMotor1()) {
//		qd_t initialCurrent = {0}; // Define based on your motor specs
//		MC_SetCurrentReferenceMotor1(initialCurrent);
//		MC_ProgramPositionCommandMotor1(targetPosition, 0); // Immediate movement
//
//		while (MC_GetControlPositionStatusMotor1() != TC_TARGET_POSITION_REACHED) {
//		  osDelay(10);  // Check every 10 ms
//		}
//
//		MC_StopMotor1();
//	  }
//	  startMotor = false;  // Reset the flag
//	}

  /* Start scheduler */
  osKernelStart();

  /* We should never get here as control is now taken by the scheduler */

  /* Infinite loop */
  while (1)
  {

  }
}

void SystemClock_Config(void)
{
  RCC_OscInitTypeDef RCC_OscInitStruct = {0};
  RCC_ClkInitTypeDef RCC_ClkInitStruct = {0};

  /** Configure the main internal regulator output voltage
  */
  HAL_PWREx_ControlVoltageScaling(PWR_REGULATOR_VOLTAGE_SCALE1_BOOST);

  /** Initializes the RCC Oscillators according to the specified parameters
  * in the RCC_OscInitTypeDef structure.
  */
  RCC_OscInitStruct.OscillatorType = RCC_OSCILLATORTYPE_HSE;
  RCC_OscInitStruct.HSEState = RCC_HSE_ON;
  RCC_OscInitStruct.PLL.PLLState = RCC_PLL_ON;
  RCC_OscInitStruct.PLL.PLLSource = RCC_PLLSOURCE_HSE;
  RCC_OscInitStruct.PLL.PLLM = RCC_PLLM_DIV6;
  RCC_OscInitStruct.PLL.PLLN = 85;
  RCC_OscInitStruct.PLL.PLLP = RCC_PLLP_DIV8;
  RCC_OscInitStruct.PLL.PLLQ = RCC_PLLQ_DIV2;
  RCC_OscInitStruct.PLL.PLLR = RCC_PLLR_DIV2;
  if (HAL_RCC_OscConfig(&RCC_OscInitStruct) != HAL_OK)
  {
    Error_Handler();
  }

  /** Initializes the CPU, AHB and APB buses clocks
  */
  RCC_ClkInitStruct.ClockType = RCC_CLOCKTYPE_HCLK|RCC_CLOCKTYPE_SYSCLK
                              |RCC_CLOCKTYPE_PCLK1|RCC_CLOCKTYPE_PCLK2;
  RCC_ClkInitStruct.SYSCLKSource = RCC_SYSCLKSOURCE_PLLCLK;
  RCC_ClkInitStruct.AHBCLKDivider = RCC_SYSCLK_DIV1;
  RCC_ClkInitStruct.APB1CLKDivider = RCC_HCLK_DIV1;
  RCC_ClkInitStruct.APB2CLKDivider = RCC_HCLK_DIV1;

  if (HAL_RCC_ClockConfig(&RCC_ClkInitStruct, FLASH_LATENCY_4) != HAL_OK)
  {
    Error_Handler();
  }

  /** Enables the Clock Security System
  */
  HAL_RCC_EnableCSS();
}

/**
  * @brief NVIC Configuration.
  * @retval None
  */
static void MX_NVIC_Init(void)
{
  /* USART2_IRQn interrupt configuration */
  HAL_NVIC_SetPriority(USART2_IRQn, 8, 0);
  HAL_NVIC_EnableIRQ(USART2_IRQn);
  /* DMA1_Channel1_IRQn interrupt configuration */
  HAL_NVIC_SetPriority(DMA1_Channel1_IRQn, 8, 0);
  HAL_NVIC_EnableIRQ(DMA1_Channel1_IRQn);
  /* TIM1_BRK_TIM15_IRQn interrupt configuration */
  HAL_NVIC_SetPriority(TIM1_BRK_TIM15_IRQn, 9, 0);
  HAL_NVIC_EnableIRQ(TIM1_BRK_TIM15_IRQn);
  /* TIM1_UP_TIM16_IRQn interrupt configuration */
  HAL_NVIC_SetPriority(TIM1_UP_TIM16_IRQn, 5, 0);
  HAL_NVIC_EnableIRQ(TIM1_UP_TIM16_IRQn);
  /* ADC1_2_IRQn interrupt configuration */
  HAL_NVIC_SetPriority(ADC1_2_IRQn, 7, 0);
  HAL_NVIC_EnableIRQ(ADC1_2_IRQn);
  /* TIM2_IRQn interrupt configuration */
  HAL_NVIC_SetPriority(TIM2_IRQn, 8, 0);
  HAL_NVIC_EnableIRQ(TIM2_IRQn);
  /* EXTI15_10_IRQn interrupt configuration */
  HAL_NVIC_SetPriority(EXTI15_10_IRQn, 8, 0);
  HAL_NVIC_EnableIRQ(EXTI15_10_IRQn);
}

static void MX_ADC1_Init(void)
{

  ADC_MultiModeTypeDef multimode = {0};
  ADC_InjectionConfTypeDef sConfigInjected = {0};
  ADC_ChannelConfTypeDef sConfig = {0};

  /** Common config
  */
  hadc1.Instance = ADC1;
  hadc1.Init.ClockPrescaler = ADC_CLOCK_ASYNC_DIV1;
  hadc1.Init.Resolution = ADC_RESOLUTION_12B;
  hadc1.Init.DataAlign = ADC_DATAALIGN_LEFT;
  hadc1.Init.GainCompensation = 0;
  hadc1.Init.ScanConvMode = ADC_SCAN_ENABLE;
  hadc1.Init.EOCSelection = ADC_EOC_SINGLE_CONV;
  hadc1.Init.LowPowerAutoWait = DISABLE;
  hadc1.Init.ContinuousConvMode = DISABLE;
  hadc1.Init.NbrOfConversion = 2;
  hadc1.Init.DiscontinuousConvMode = DISABLE;
  hadc1.Init.ExternalTrigConv = ADC_SOFTWARE_START;
  hadc1.Init.ExternalTrigConvEdge = ADC_EXTERNALTRIGCONVEDGE_NONE;
  hadc1.Init.DMAContinuousRequests = DISABLE;
  hadc1.Init.Overrun = ADC_OVR_DATA_PRESERVED;
  hadc1.Init.OversamplingMode = DISABLE;
  if (HAL_ADC_Init(&hadc1) != HAL_OK)
  {
    Error_Handler();
  }

  /** Configure the ADC multi-mode
  */
  multimode.Mode = ADC_MODE_INDEPENDENT;
  if (HAL_ADCEx_MultiModeConfigChannel(&hadc1, &multimode) != HAL_OK)
  {
    Error_Handler();
  }

  /** Configure Injected Channel
  */
  sConfigInjected.InjectedChannel = ADC_CHANNEL_1;
  sConfigInjected.InjectedRank = ADC_INJECTED_RANK_1;
  sConfigInjected.InjectedSamplingTime = ADC_SAMPLETIME_6CYCLES_5;
  sConfigInjected.InjectedSingleDiff = ADC_SINGLE_ENDED;
  sConfigInjected.InjectedOffsetNumber = ADC_OFFSET_NONE;
  sConfigInjected.InjectedOffset = 0;
  sConfigInjected.InjectedNbrOfConversion = 3;
  sConfigInjected.InjectedDiscontinuousConvMode = DISABLE;
  sConfigInjected.AutoInjectedConv = DISABLE;
  sConfigInjected.QueueInjectedContext = DISABLE;
  sConfigInjected.ExternalTrigInjecConv = ADC_EXTERNALTRIGINJEC_T1_TRGO;
  sConfigInjected.ExternalTrigInjecConvEdge = ADC_EXTERNALTRIGINJECCONV_EDGE_RISING;
  sConfigInjected.InjecOversamplingMode = DISABLE;
  if (HAL_ADCEx_InjectedConfigChannel(&hadc1, &sConfigInjected) != HAL_OK)
  {
    Error_Handler();
  }

  /** Configure Injected Channel
  */
  sConfigInjected.InjectedChannel = ADC_CHANNEL_7;
  sConfigInjected.InjectedRank = ADC_INJECTED_RANK_2;
  if (HAL_ADCEx_InjectedConfigChannel(&hadc1, &sConfigInjected) != HAL_OK)
  {
    Error_Handler();
  }

  /** Configure Injected Channel
  */
  sConfigInjected.InjectedChannel = ADC_CHANNEL_6;
  sConfigInjected.InjectedRank = ADC_INJECTED_RANK_3;
  if (HAL_ADCEx_InjectedConfigChannel(&hadc1, &sConfigInjected) != HAL_OK)
  {
    Error_Handler();
  }

  /** Configure Regular Channel
  */
  sConfig.Channel = ADC_CHANNEL_2;
  sConfig.Rank = ADC_REGULAR_RANK_1;
  sConfig.SamplingTime = ADC_SAMPLETIME_47CYCLES_5;
  sConfig.SingleDiff = ADC_SINGLE_ENDED;
  sConfig.OffsetNumber = ADC_OFFSET_NONE;
  sConfig.Offset = 0;
  if (HAL_ADC_ConfigChannel(&hadc1, &sConfig) != HAL_OK)
  {
    Error_Handler();
  }

  /** Configure Regular Channel
  */
  sConfig.Channel = ADC_CHANNEL_8;
  sConfig.Rank = ADC_REGULAR_RANK_2;
  if (HAL_ADC_ConfigChannel(&hadc1, &sConfig) != HAL_OK)
  {
    Error_Handler();
  }

}

static void MX_CORDIC_Init(void)
{

  hcordic.Instance = CORDIC;
  if (HAL_CORDIC_Init(&hcordic) != HAL_OK)
  {
    Error_Handler();
  }

}

static void MX_DAC1_Init(void)
{

  DAC_ChannelConfTypeDef sConfig = {0};

  /** DAC Initialization
  */
  hdac1.Instance = DAC1;
  if (HAL_DAC_Init(&hdac1) != HAL_OK)
  {
    Error_Handler();
  }

  /** DAC channel OUT1 config
  */
  sConfig.DAC_HighFrequency = DAC_HIGH_FREQUENCY_INTERFACE_MODE_AUTOMATIC;
  sConfig.DAC_DMADoubleDataMode = DISABLE;
  sConfig.DAC_SignedFormat = DISABLE;
  sConfig.DAC_SampleAndHold = DAC_SAMPLEANDHOLD_DISABLE;
  sConfig.DAC_Trigger = DAC_TRIGGER_SOFTWARE;
  sConfig.DAC_Trigger2 = DAC_TRIGGER_NONE;
  sConfig.DAC_OutputBuffer = DAC_OUTPUTBUFFER_DISABLE;
  sConfig.DAC_ConnectOnChipPeripheral = DAC_CHIPCONNECT_EXTERNAL;
  sConfig.DAC_UserTrimming = DAC_TRIMMING_FACTORY;
  if (HAL_DAC_ConfigChannel(&hdac1, &sConfig, DAC_CHANNEL_1) != HAL_OK)
  {
    Error_Handler();
  }

}

static void MX_TIM1_Init(void)
{

  TIM_MasterConfigTypeDef sMasterConfig = {0};
  TIMEx_BreakInputConfigTypeDef sBreakInputConfig = {0};
  TIM_OC_InitTypeDef sConfigOC = {0};
  TIM_BreakDeadTimeConfigTypeDef sBreakDeadTimeConfig = {0};

  htim1.Instance = TIM1;
  htim1.Init.Prescaler = ((TIM_CLOCK_DIVIDER) - 1);
  htim1.Init.CounterMode = TIM_COUNTERMODE_CENTERALIGNED1;
  htim1.Init.Period = ((PWM_PERIOD_CYCLES) / 2);
  htim1.Init.ClockDivision = TIM_CLOCKDIVISION_DIV2;
  htim1.Init.RepetitionCounter = (REP_COUNTER);
  htim1.Init.AutoReloadPreload = TIM_AUTORELOAD_PRELOAD_DISABLE;
  if (HAL_TIM_PWM_Init(&htim1) != HAL_OK)
  {
    Error_Handler();
  }
  sMasterConfig.MasterOutputTrigger = TIM_TRGO_OC4REF;
  sMasterConfig.MasterOutputTrigger2 = TIM_TRGO2_RESET;
  sMasterConfig.MasterSlaveMode = TIM_MASTERSLAVEMODE_DISABLE;
  if (HAL_TIMEx_MasterConfigSynchronization(&htim1, &sMasterConfig) != HAL_OK)
  {
    Error_Handler();
  }
  sBreakInputConfig.Source = TIM_BREAKINPUTSOURCE_BKIN;
  sBreakInputConfig.Enable = TIM_BREAKINPUTSOURCE_ENABLE;
  sBreakInputConfig.Polarity = TIM_BREAKINPUTSOURCE_POLARITY_LOW;
  if (HAL_TIMEx_ConfigBreakInput(&htim1, TIM_BREAKINPUT_BRK, &sBreakInputConfig) != HAL_OK)
  {
    Error_Handler();
  }
  sConfigOC.OCMode = TIM_OCMODE_PWM1;
  sConfigOC.Pulse = ((PWM_PERIOD_CYCLES) / 4);
  sConfigOC.OCPolarity = TIM_OCPOLARITY_HIGH;
  sConfigOC.OCNPolarity = TIM_OCNPOLARITY_LOW;
  sConfigOC.OCFastMode = TIM_OCFAST_DISABLE;
  sConfigOC.OCIdleState = TIM_OCIDLESTATE_RESET;
  sConfigOC.OCNIdleState = TIM_OCNIDLESTATE_SET;
  if (HAL_TIM_PWM_ConfigChannel(&htim1, &sConfigOC, TIM_CHANNEL_1) != HAL_OK)
  {
    Error_Handler();
  }
  if (HAL_TIM_PWM_ConfigChannel(&htim1, &sConfigOC, TIM_CHANNEL_2) != HAL_OK)
  {
    Error_Handler();
  }
  if (HAL_TIM_PWM_ConfigChannel(&htim1, &sConfigOC, TIM_CHANNEL_3) != HAL_OK)
  {
    Error_Handler();
  }
  sConfigOC.OCMode = TIM_OCMODE_PWM2;
  sConfigOC.Pulse = (((PWM_PERIOD_CYCLES) / 2) - (HTMIN));
  sConfigOC.OCNPolarity = TIM_OCNPOLARITY_HIGH;
  sConfigOC.OCNIdleState = TIM_OCNIDLESTATE_RESET;
  if (HAL_TIM_PWM_ConfigChannel(&htim1, &sConfigOC, TIM_CHANNEL_4) != HAL_OK)
  {
    Error_Handler();
  }
  sBreakDeadTimeConfig.OffStateRunMode = TIM_OSSR_ENABLE;
  sBreakDeadTimeConfig.OffStateIDLEMode = TIM_OSSI_ENABLE;
  sBreakDeadTimeConfig.LockLevel = TIM_LOCKLEVEL_OFF;
  sBreakDeadTimeConfig.DeadTime = ((DEAD_TIME_COUNTS) / 2);
  sBreakDeadTimeConfig.BreakState = TIM_BREAK_ENABLE;
  sBreakDeadTimeConfig.BreakPolarity = TIM_BREAKPOLARITY_HIGH;
  sBreakDeadTimeConfig.BreakFilter = 3;
  sBreakDeadTimeConfig.BreakAFMode = TIM_BREAK_AFMODE_INPUT;
  sBreakDeadTimeConfig.Break2State = TIM_BREAK2_DISABLE;
  sBreakDeadTimeConfig.Break2Polarity = TIM_BREAK2POLARITY_HIGH;
  sBreakDeadTimeConfig.Break2Filter = 3;
  sBreakDeadTimeConfig.Break2AFMode = TIM_BREAK_AFMODE_INPUT;
  sBreakDeadTimeConfig.AutomaticOutput = TIM_AUTOMATICOUTPUT_DISABLE;
  if (HAL_TIMEx_ConfigBreakDeadTime(&htim1, &sBreakDeadTimeConfig) != HAL_OK)
  {
    Error_Handler();
  }
  HAL_TIM_MspPostInit(&htim1);

}

static void MX_TIM2_Init(void)
{

  TIM_Encoder_InitTypeDef sConfig = {0};
  TIM_MasterConfigTypeDef sMasterConfig = {0};

  htim2.Instance = TIM2;
  htim2.Init.Prescaler = 0;
  htim2.Init.CounterMode = TIM_COUNTERMODE_UP;
  htim2.Init.Period = M1_PULSE_NBR;
  htim2.Init.ClockDivision = TIM_CLOCKDIVISION_DIV1;
  htim2.Init.AutoReloadPreload = TIM_AUTORELOAD_PRELOAD_DISABLE;
  sConfig.EncoderMode = TIM_ENCODERMODE_TI12;
  sConfig.IC1Polarity = TIM_ICPOLARITY_RISING;
  sConfig.IC1Selection = TIM_ICSELECTION_DIRECTTI;
  sConfig.IC1Prescaler = TIM_ICPSC_DIV1;
  sConfig.IC1Filter = M1_ENC_IC_FILTER;
  sConfig.IC2Polarity = TIM_ICPOLARITY_RISING;
  sConfig.IC2Selection = TIM_ICSELECTION_DIRECTTI;
  sConfig.IC2Prescaler = TIM_ICPSC_DIV1;
  sConfig.IC2Filter = M1_ENC_IC_FILTER;
  if (HAL_TIM_Encoder_Init(&htim2, &sConfig) != HAL_OK)
  {
    Error_Handler();
  }
  sMasterConfig.MasterOutputTrigger = TIM_TRGO_RESET;
  sMasterConfig.MasterSlaveMode = TIM_MASTERSLAVEMODE_DISABLE;
  if (HAL_TIMEx_MasterConfigSynchronization(&htim2, &sMasterConfig) != HAL_OK)
  {
    Error_Handler();
  }

}

static void MX_USART2_UART_Init(void)
{

  huart2.Instance = USART2;
  huart2.Init.BaudRate = 115200;
  huart2.Init.WordLength = UART_WORDLENGTH_8B;
  huart2.Init.StopBits = UART_STOPBITS_1;
  huart2.Init.Parity = UART_PARITY_NONE;
  huart2.Init.Mode = UART_MODE_TX_RX;
  huart2.Init.HwFlowCtl = UART_HWCONTROL_NONE;
  huart2.Init.OverSampling = UART_OVERSAMPLING_16;
  huart2.Init.OneBitSampling = UART_ONE_BIT_SAMPLE_DISABLE;
  huart2.Init.ClockPrescaler = UART_PRESCALER_DIV1;
  huart2.AdvancedInit.AdvFeatureInit = UART_ADVFEATURE_NO_INIT;
  if (HAL_UART_Init(&huart2) != HAL_OK)
  {
    Error_Handler();
  }
  if (HAL_UARTEx_SetTxFifoThreshold(&huart2, UART_TXFIFO_THRESHOLD_1_8) != HAL_OK)
  {
    Error_Handler();
  }
  if (HAL_UARTEx_SetRxFifoThreshold(&huart2, UART_RXFIFO_THRESHOLD_1_8) != HAL_OK)
  {
    Error_Handler();
  }
  if (HAL_UARTEx_DisableFifoMode(&huart2) != HAL_OK)
  {
    Error_Handler();
  }

}

static void MX_DMA_Init(void)
{

  /* DMA controller clock enable */
  __HAL_RCC_DMAMUX1_CLK_ENABLE();
  __HAL_RCC_DMA1_CLK_ENABLE();

}

static void MX_GPIO_Init(void)
{
  GPIO_InitTypeDef GPIO_InitStruct = {0};

  /* GPIO Ports Clock Enable */
  __HAL_RCC_GPIOC_CLK_ENABLE();
  __HAL_RCC_GPIOF_CLK_ENABLE();
  __HAL_RCC_GPIOA_CLK_ENABLE();
  __HAL_RCC_GPIOB_CLK_ENABLE();

  /*Configure GPIO pin : Start_Stop_Pin */
  GPIO_InitStruct.Pin = Start_Stop_Pin;
  GPIO_InitStruct.Mode = GPIO_MODE_IT_FALLING;
  GPIO_InitStruct.Pull = GPIO_NOPULL;
  HAL_GPIO_Init(Start_Stop_GPIO_Port, &GPIO_InitStruct);

}

__weak void startMediumFrequencyTask(void const * argument)
{
  /* USER CODE BEGIN 5 */
  /* Infinite loop */
  for(;;)
  {
//	if (startMotor) {
//	  if (MC_StartMotor1()) {
//		qd_t initialCurrent = {0}; // Define based on your motor specs
//		MC_SetCurrentReferenceMotor1(initialCurrent);
//		MC_ProgramPositionCommandMotor1(targetPosition, 0); // Immediate movement
//
//		while (MC_GetControlPositionStatusMotor1() != TC_TARGET_POSITION_REACHED) {
//		  osDelay(10);  // Check every 10 ms
//		}
//
//		MC_StopMotor1();
//	  }
//	  startMotor = false;  // Reset the flag
//	}
    osDelay(1);
  }
  /* USER CODE END 5 */
}

void HAL_TIM_PeriodElapsedCallback(TIM_HandleTypeDef *htim)
{
  if (htim->Instance == TIM6) {
    HAL_IncTick();
  }
}

void Error_Handler(void)
{
  __disable_irq();
  while (1)
  {
  }
}
